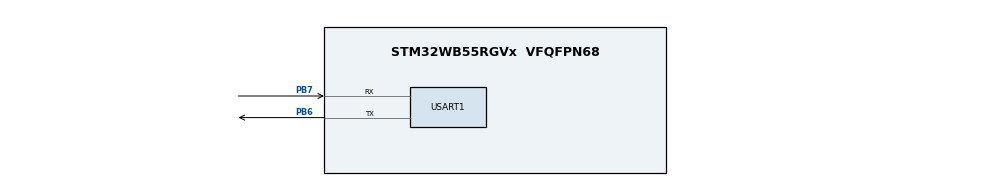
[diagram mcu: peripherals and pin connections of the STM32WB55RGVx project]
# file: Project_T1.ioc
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Mcu.Family=STM32WB
Mcu.Name=STM32WB55RGVx
Mcu.Package=VFQFPN68
NVIC.PriorityGroup=NVIC_PRIORITYGROUP_4
NVIC.USART1_IRQn=true\:0\:0\:false\:false\:true\:true\:true\:true
OSC_IN.Mode=HSE-External-Oscillator
OSC_IN.Signal=RCC_OSC_IN
OSC_OUT.Mode=HSE-External-Oscillator
OSC_OUT.Signal=RCC_OSC_OUT
PA13.Mode=Serial_Wire
PA13.Signal=SYS_JTMS-SWDIO
PA14.Mode=Serial_Wire
PA14.Signal=SYS_JTCK-SWCLK
PB6.Mode=Asynchronous
PB6.Signal=USART1_TX
PB7.Mode=Asynchronous
PB7.Signal=USART1_RX
PC14-OSC32_IN.Mode=LSE-External-Oscillator
PC14-OSC32_IN.Signal=RCC_OSC32_IN
PC15-OSC32_OUT.Mode=LSE-External-Oscillator
PC15-OSC32_OUT.Signal=RCC_OSC32_OUT
ProjectManager.HeapSize=0x200
ProjectManager.StackSize=0x400
ProjectManager.TargetToolchain=STM32CubeIDE
RCC.ADCFreq_Value=64000000
RCC.AHB2CLKDivider=RCC_SYSCLK_DIV2
RCC.AHBFreq_Value=64000000
RCC.APB1Freq_Value=64000000
RCC.APB1TimFreq_Value=64000000
RCC.APB2Freq_Value=64000000
RCC.APB2TimFreq_Value=64000000
RCC.APB3Freq_Value=16000000
RCC.Cortex2_Div=SYSTICK_CLKSOURCE_HCLK_DIV8
RCC.CortexFreq_Value=64000000
RCC.HCLKFreq_Value=64000000
RCC.HSE_VALUE=32000000
RCC.HSI48_VALUE=48000000
RCC.HSI_VALUE=16000000
RCC.PLLM=RCC_PLLM_DIV2
RCC.PLLSourceVirtual=RCC_PLLSOURCE_HSE
RCC.SYSCLKFreq_VALUE=64000000
RCC.SYSCLKSource=RCC_SYSCLKSOURCE_PLLCLK
RCC.USBFreq_Value=64000000
RCC.VCOOutputFreq_Value=128000000
USART1.VirtualMode-Asynchronous=VM_ASYNC
VP_MEMORYMAP_VS_MEMORYMAP.Mode=CurAppReg
board=custom

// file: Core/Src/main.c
/* USER CODE BEGIN Header */
/**
  ******************************************************************************
  * @file           : main.c
  * @brief          : Main program body
  ******************************************************************************
  * @attention
  *
  * Copyright (c) 2025 STMicroelectronics.
  * All rights reserved.
  *
  * This software is licensed under terms that can be found in the LICENSE file
  * in the root directory of this software component.
  * If no LICENSE file comes with this software, it is provided AS-IS.
  *
  ******************************************************************************
  */
  /* USER CODE END Header */
  /* Includes ------------------------------------------------------------------*/
#include "main.h"
#include "memorymap.h"
#include "usart.h"
#include "gpio.h"

/* USER CODE BEGIN Includes */
#include "Serial_IT.h"
/* USER CODE END Includes */

void SystemClock_Config( void );
void PeriphCommonClock_Config( void );

int main( void )
{

  /* MCU Configuration--------------------------------------------------------*/

  /* Reset of all peripherals, Initializes the Flash interface and the Systick. */

  /* System interrupt init*/
  NVIC_SetPriorityGrouping( NVIC_PRIORITYGROUP_4 );

  /* SysTick_IRQn interrupt configuration */
  NVIC_SetPriority( SysTick_IRQn, NVIC_EncodePriority( NVIC_GetPriorityGrouping(), 15, 0 ) );

  /* Configure the system clock */
  SystemClock_Config();

  /* Configure the peripherals common clocks */
  PeriphCommonClock_Config();

  /* Initialize all configured peripherals */
  MX_GPIO_Init();
  MX_USART1_UART_Init();
  /* USER CODE BEGIN 2 */
  SerialItEnable();
  /* USER CODE END 2 */

  /* Infinite loop */
  while ( 1 )
  {

  }
}

void SystemClock_Config( void )
{
  LL_FLASH_SetLatency( LL_FLASH_LATENCY_3 );
  while ( LL_FLASH_GetLatency() != LL_FLASH_LATENCY_3 )
  {
  }

  /* HSE configuration and activation */
  LL_RCC_HSE_Enable();
  while ( LL_RCC_HSE_IsReady() != 1 )
  {
  }

  /* HSI configuration and activation */
  LL_RCC_HSI_Enable();
  while ( LL_RCC_HSI_IsReady() != 1 )
  {
  }

  /* Main PLL configuration and activation */
  LL_RCC_PLL_ConfigDomain_SYS( LL_RCC_PLLSOURCE_HSE, LL_RCC_PLLM_DIV_2, 8, LL_RCC_PLLR_DIV_2 );
  LL_RCC_PLL_Enable();
  LL_RCC_PLL_EnableDomain_SYS();
  while ( LL_RCC_PLL_IsReady() != 1 )
  {
  }

  /* Sysclk activation on the main PLL */
  /* Set CPU1 prescaler*/
  LL_RCC_SetAHBPrescaler( LL_RCC_SYSCLK_DIV_1 );

  /* Set CPU2 prescaler*/
  LL_C2_RCC_SetAHBPrescaler( LL_RCC_SYSCLK_DIV_2 );

  LL_RCC_SetSysClkSource( LL_RCC_SYS_CLKSOURCE_PLL );
  while ( LL_RCC_GetSysClkSource() != LL_RCC_SYS_CLKSOURCE_STATUS_PLL )
  {
  }

  /* Set AHB SHARED prescaler*/
  LL_RCC_SetAHB4Prescaler( LL_RCC_SYSCLK_DIV_1 );

  /* Set APB1 prescaler*/
  LL_RCC_SetAPB1Prescaler( LL_RCC_APB1_DIV_1 );

  /* Set APB2 prescaler*/
  LL_RCC_SetAPB2Prescaler( LL_RCC_APB2_DIV_1 );

  LL_Init1msTick( 64000000 );

  /* Update CMSIS variable (which can be updated also through SystemCoreClockUpdate function) */
  LL_SetSystemCoreClock( 64000000 );
}

void PeriphCommonClock_Config( void )
{
  LL_RCC_SetSMPSClockSource( LL_RCC_SMPS_CLKSOURCE_HSI );
  LL_RCC_SetSMPSPrescaler( LL_RCC_SMPS_DIV_1 );
  LL_RCC_SetRFWKPClockSource( LL_RCC_RFWKP_CLKSOURCE_NONE );
}

void Error_Handler( void )
{
  __disable_irq();
  while ( 1 )
  {
  }
}
